# tle984x register map
Vendor: Infineon; File version: 1.9.5
CPU: CM0 r2p1, little endian, no MPU, no FPU, 2 interrupt priority bits
Registers are 32-bit, read-write, reset 0x0 unless marked. A register's access mark holds for its fields unless they carry their own. Offsets are from the block's base; [hi:lo] are bit positions; {n}, {i} and the like mark numbered series; 'fields as' and 'values as' point back to an identical list.

## SCUPM — System Control Unit - Power Modules (SCU-PM)
Base 0x50006000
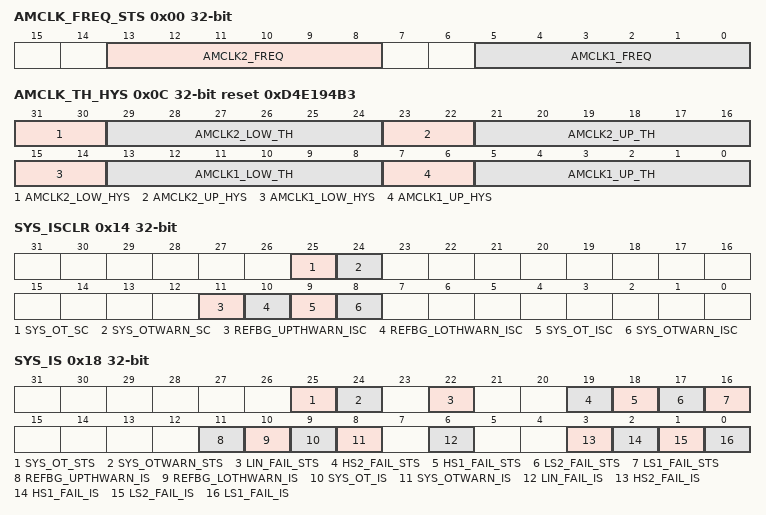
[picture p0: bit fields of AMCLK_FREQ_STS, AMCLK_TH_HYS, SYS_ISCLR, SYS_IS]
0x00 AMCLK_FREQ_STS ro — Analog module clock frequency status register
  [13:8] AMCLK2_FREQ — Current frequency of analog module clock 2 (TFILT_CLK)
  [5:0] AMCLK1_FREQ — Current frequency of analog module clock system clock (MI_CLK)
0x04 AMCLK_CTRL reset 0x1 — Analog module clock control register
  [0] CLKWDT_PD_N — Clock watchdog power down
    0=DISABLE (Clock watchdog disabled); 1=ENABLE (Clock watchdog enabled)
0x0C AMCLK_TH_HYS reset 0xD4E194B3 — Analog module clock limit register
  [31:30] AMCLK2_LOW_HYS — Analog module clock 2 (TFILT_CLK) lower hysteresis
  [29:24] AMCLK2_LOW_TH — Analog module clock 2 (TFILT_CLK) lower limit threshold
  [23:22] AMCLK2_UP_HYS — Analog module clock 2 (TFILT_CLK) upper hysteresis
  [21:16] AMCLK2_UP_TH — Analog module clock 2 (TFILT_CLK) upper limit threshold
  [15:14] AMCLK1_LOW_HYS — Analog module clock 1 (MI_CLK) lower hysteresis
  [13:8] AMCLK1_LOW_TH — Analog module clock 1 (MI_CLK) lower limit threshold
  [7:6] AMCLK1_UP_HYS — Analog module clock 1 (MI_CLK) upper hysteresis
  [5:0] AMCLK1_UP_TH — Analog module clock 1 (MI_CLK) upper limit threshold
0x14 SYS_ISCLR — System interrupt status clear register
  [all] fields
    0=NO_CLEAR (The interrupt status is not cleared); 1=CLEAR (The interrupt status is cleared)
  [25] SYS_OT_SC wo — System overtemperature shutdown status clear
  [24] SYS_OTWARN_SC wo — System overtemperature pre-warning status clear
  [11] REFBG_UPTHWARN_ISC wo — 8-bit ADC2 reference overvoltage interrupt status clear
  [10] REFBG_LOTHWARN_ISC wo — 8-bit ADC2 reference undervoltage interrupt status clear
  [9] SYS_OT_ISC wo — System overtemperature shutdown status clear
  [8] SYS_OTWARN_ISC wo — System overtemperature pre-warning status clear
0x18 SYS_IS — System interrupt status register
  [25] SYS_OT_STS — System overtemperature shutdown (ADC2, channel 6) status
    0=INACTIVE (No status set); 1=ACTIVE (At least one status set)
  [24] SYS_OTWARN_STS — System overtemperature pre-warning (ADC2, channel 6) status
    values as SYS_OT_STS
  [22] LIN_FAIL_STS ro — LIN fail status
    values as SYS_OT_STS
  [19] HS2_FAIL_STS ro — High-side driver 2 fail status
    values as SYS_OT_STS
  [18] HS1_FAIL_STS ro — High-side driver 1 fail status
    values as SYS_OT_STS
  [17] LS2_FAIL_STS ro — Low-side driver 2 fail status
    values as SYS_OT_STS
  [16] LS1_FAIL_STS ro — Low-side driver 1 fail status
    values as SYS_OT_STS
  [11] REFBG_UPTHWARN_IS — 8-bit ADC2 reference overvoltage (ADC2, channel 3) interrupt status
    0=INACTIVE (No interrupt status set); 1=ACTIVE (At least one interrupt status set)
  [10] REFBG_LOTHWARN_IS — 8-bit ADC2 reference undervoltage (ADC2, channel 3) interrupt status
    values as REFBG_UPTHWARN_IS
  [9] SYS_OT_IS — System overtemperature shutdown (ADC2, channel 6) interrupt status
    values as REFBG_UPTHWARN_IS
  [8] SYS_OTWARN_IS — System overtemperature prewarning (ADC2, channel 6) interrupt status
    values as REFBG_UPTHWARN_IS
  [6] LIN_FAIL_IS ro — LIN fail interrupt status
    values as SYS_OT_STS
  [3] HS2_FAIL_IS ro — High-side driver 2 fail interrupt status
    values as SYS_OT_STS
  [2] HS1_FAIL_IS ro — High-side driver 1 fail interrupt status
    values as SYS_OT_STS
  [1] LS2_FAIL_IS ro — Low-side driver 2 fail interrupt status
    values as SYS_OT_STS
  [0] LS1_FAIL_IS ro — Low-side driver 1 fail interrupt status
    values as SYS_OT_STS
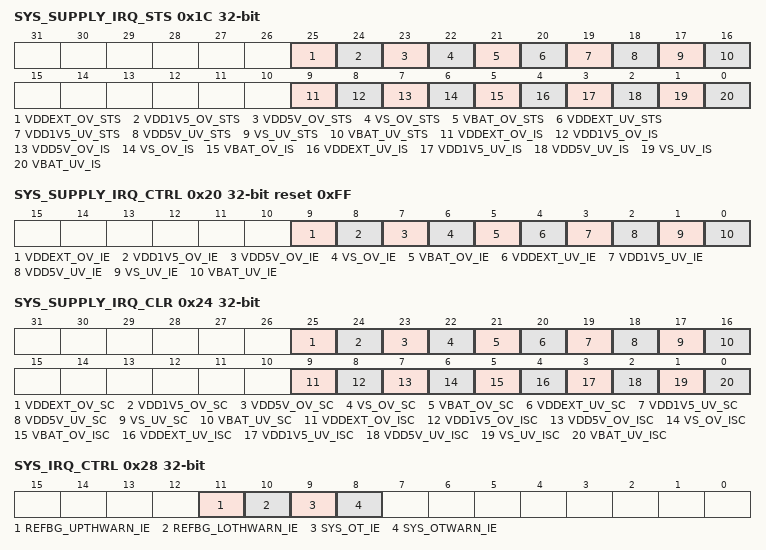
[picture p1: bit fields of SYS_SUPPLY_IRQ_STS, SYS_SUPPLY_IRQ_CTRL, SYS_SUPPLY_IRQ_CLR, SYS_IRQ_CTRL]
0x1C SYS_SUPPLY_IRQ_STS — System supply interrupt status register
  [25] VDDEXT_OV_STS — VDDEXT overvoltage status
    0=NO_OVERVOLTAGE (No overvoltage occurred); 1=OVERVOLTAGE (Overvoltage occurred)
  [24] VDD1V5_OV_STS — VDDC overvoltage status
    values as VDDEXT_OV_STS
  [23] VDD5V_OV_STS — VDDP overvoltage status
    values as VDDEXT_OV_STS
  [22] VS_OV_STS — VS overvoltage status
    values as VDDEXT_OV_STS
  [21] VBAT_OV_STS — VBAT overvoltage status
    values as VDDEXT_OV_STS
  [20] VDDEXT_UV_STS — VDDEXT undervoltage status
    0=NO_UNDERVOLTAGE (No undervoltage occurred); 1=UNDERVOLTAGE (Undervoltage occurred)
  [19] VDD1V5_UV_STS — VDDC undervoltage status
    values as VDDEXT_UV_STS
  [18] VDD5V_UV_STS — VDDP undervoltage status
    values as VDDEXT_UV_STS
  [17] VS_UV_STS — VS undervoltage status
    values as VDDEXT_UV_STS
  [16] VBAT_UV_STS — VBAT undervoltage status
    values as VDDEXT_UV_STS
  [9] VDDEXT_OV_IS — VDDEXT overvoltage interrupt status
    0=NO_INTERRUPT (No undervoltage interrupt occurred); 1=INTERRUPT (Undervoltage interrupt occurred)
  [8] VDD1V5_OV_IS — VDDC overvoltage interrupt status
    values as VDDEXT_OV_IS
  [7] VDD5V_OV_IS — VDDP overvoltage interrupt status
    values as VDDEXT_OV_IS
  [6] VS_OV_IS — VS overvoltage interrupt status
    values as VDDEXT_OV_IS
  [5] VBAT_OV_IS — VBAT overvoltage interrupt status
    values as VDDEXT_OV_IS
  [4] VDDEXT_UV_IS — VDDEXT undervoltage interrupt status
    values as VDDEXT_OV_IS
  [3] VDD1V5_UV_IS — VDDC undervoltage interrupt status
    values as VDDEXT_OV_IS
  [2] VDD5V_UV_IS — VDDP undervoltage interrupt status
    values as VDDEXT_OV_IS
  [1] VS_UV_IS — VS undervoltage interrupt status
    values as VDDEXT_OV_IS
  [0] VBAT_UV_IS — VBAT undervoltage interrupt status
    values as VDDEXT_OV_IS
0x20 SYS_SUPPLY_IRQ_CTRL reset 0xFF — System supply interrupt control register
  [all] fields
    0=DISABLED (Interrupt is disabled); 1=ENABLED (Interrupt is enabled)
  [9] VDDEXT_OV_IE — VDDEXT overvoltage interrupt enable
  [8] VDD1V5_OV_IE — VDDC overvoltage interrupt enable
  [7] VDD5V_OV_IE — VDDP overvoltage interrupt enable
  [6] VS_OV_IE — VS overvoltage interrupt enable
  [5] VBAT_OV_IE — VBAT overvoltage interrupt enable
  [4] VDDEXT_UV_IE — VDDEXT undervoltage interrupt enable
  [3] VDD1V5_UV_IE — VDDC undervoltage interrupt enable
  [2] VDD5V_UV_IE — VDDP undervoltage interrupt enable
  [1] VS_UV_IE — VS undervoltage interrupt enable
  [0] VBAT_UV_IE — VBAT undervoltage interrupt enable
0x24 SYS_SUPPLY_IRQ_CLR — System supply interrupt status clear register
  [all] fields
    values as the fields of SYS_ISCLR
  [25] VDDEXT_OV_SC wo — VDDEXT overvoltage status clear
  [24] VDD1V5_OV_SC wo — VDDC overvoltage status clear
  [23] VDD5V_OV_SC wo — VDDP overvoltage status clear
  [22] VS_OV_SC wo — VS overvoltage status clear
  [21] VBAT_OV_SC wo — VBAT overvoltage status clear
  [20] VDDEXT_UV_SC wo — VDDEXT undervoltage status clear
  [19] VDD1V5_UV_SC wo — VDDC undervoltage status clear
  [18] VDD5V_UV_SC wo — VDDP undervoltage status clear
  [17] VS_UV_SC wo — VS undervoltage status clear
  [16] VBAT_UV_SC wo — VBAT undervoltage status clear
  [9] VDDEXT_OV_ISC wo — VDDEXT overvoltage interrupt status clear
  [8] VDD1V5_OV_ISC wo — VDDC overvoltage interrupt status clear
  [7] VDD5V_OV_ISC wo — VDDP overvoltage interrupt status clear
  [6] VS_OV_ISC wo — VS overvoltage interrupt status clear
  [5] VBAT_OV_ISC wo — VBAT overvoltage interrupt status clear
  [4] VDDEXT_UV_ISC wo — VDDEXT undervoltage interrupt status clear
  [3] VDD1V5_UV_ISC wo — VDDC undervoltage interrupt status clear
  [2] VDD5V_UV_ISC wo — VDDP undervoltage interrupt status clear
  [1] VS_UV_ISC wo — VS undervoltage interrupt status clear
  [0] VBAT_UV_ISC wo — VBAT undervoltage interrupt status clear
0x28 SYS_IRQ_CTRL — System interrupt control register
  [all] fields
    values as the fields of SYS_SUPPLY_IRQ_CTRL
  [11] REFBG_UPTHWARN_IE — Reference voltage overvoltage interrupt enable
  [10] REFBG_LOTHWARN_IE — Reference voltage undervoltage interrupt enable
  [9] SYS_OT_IE — System overtemperature shutdown interrupt enable (leads to shutdown of system)
  [8] SYS_OTWARN_IE — System overtemperature warning interrupt enable
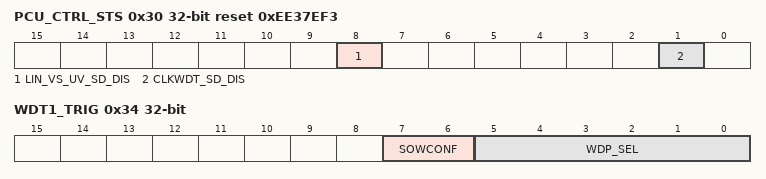
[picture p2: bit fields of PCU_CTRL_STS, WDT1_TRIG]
0x30 PCU_CTRL_STS reset 0xEE37EF3 — Power control unit control status register
  [8] LIN_VS_UV_SD_DIS — LIN module VS undervoltage transmitter shutdown
    0=ENABLE (Automatic shutdown for power modules in case of VS undervoltage enabled); 1=DISABLE (Automatic shutdown for power modules in case of VS undervoltage disabled)
  [1] CLKWDT_SD_DIS — Power modules clock watchdog shutdown disable
    0=ENABLE (Power devices will be switched off when clock watchdog occurs); 1=DISABLE (Power devices will not be shut down when clock watchdog occurs)
0x34 WDT1_TRIG — WDT1 watchdog control register
  [7:6] SOWCONF — Short open window configuration
    0=DIS (Short open windows disabled); 1=SOW1 (One successive short open window allowed); 2=SOW2 (Two successive short open windows allowed); 3=SOW3 (Three successive short open windows allowed)
  [5:0] WDP_SEL — Watchdog period selection and trigger
    0=SOW_TRIG (Trigger short open window); 1=WP1_1 (Watchdog period {$x*16} ms ({$x}*16)); 2=WP2_2 (Watchdog period {$x*16} ms ({$x}*16)); 3=WP3_3 (Watchdog period {$x*16} ms ({$x}*16)); 4=WP4_4 (Watchdog period {$x*16} ms ({$x}*16)); 5=WP5_5 (Watchdog period {$x*16} ms ({$x}*16)); 6=WP6_6 (Watchdog period {$x*16} ms ({$x}*16)); 7=WP7_7 (Watchdog period {$x*16} ms ({$x}*16)); 8=WP8_8 (Watchdog period {$x*16} ms ({$x}*16)); 9=WP9_9 (Watchdog period {$x*16} ms ({$x}*16)); 10=WP10_10 (Watchdog period {$x*16} ms ({$x}*16)); 11=WP11_11 (Watchdog period {$x*16} ms ({$x}*16)); 12=WP12_12 (Watchdog period {$x*16} ms ({$x}*16)); 13=WP13_13 (Watchdog period {$x*16} ms ({$x}*16)); 14=WP14_14 (Watchdog period {$x*16} ms ({$x}*16)); 15=WP15_15 (Watchdog period {$x*16} ms ({$x}*16)); 16=WP16_16 (Watchdog period {$x*16} ms ({$x}*16)); 17=WP17_17 (Watchdog period {$x*16} ms ({$x}*16)); 18=WP18_18 (Watchdog period {$x*16} ms ({$x}*16)); 19=WP19_19 (Watchdog period {$x*16} ms ({$x}*16)); 20=WP20_20 (Watchdog period {$x*16} ms ({$x}*16)); 21=WP21_21 (Watchdog period {$x*16} ms ({$x}*16)); 22=WP22_22 (Watchdog period {$x*16} ms ({$x}*16)); 23=WP23_23 (Watchdog period {$x*16} ms ({$x}*16)); 24=WP24_24 (Watchdog period {$x*16} ms ({$x}*16)); 25=WP25_25 (Watchdog period {$x*16} ms ({$x}*16)); 26=WP26_26 (Watchdog period {$x*16} ms ({$x}*16)); 27=WP27_27 (Watchdog period {$x*16} ms ({$x}*16)); 28=WP28_28 (Watchdog period {$x*16} ms ({$x}*16)); 29=WP29_29 (Watchdog period {$x*16} ms ({$x}*16)); 30=WP30_30 (Watchdog period {$x*16} ms ({$x}*16)); 31=WP31_31 (Watchdog period {$x*16} ms ({$x}*16)); 32=WP32_32 (Watchdog period {$x*16} ms ({$x}*16)); 33=WP33_33 (Watchdog period {$x*16} ms ({$x}*16)); 34=WP34_34 (Watchdog period {$x*16} ms ({$x}*16)); 35=WP35_35 (Watchdog period {$x*16} ms ({$x}*16)); 36=WP36_36 (Watchdog period {$x*16} ms ({$x}*16)); 37=WP37_37 (Watchdog period {$x*16} ms ({$x}*16)); 38=WP38_38 (Watchdog period {$x*16} ms ({$x}*16)); 39=WP39_39 (Watchdog period {$x*16} ms ({$x}*16)); 40=WP40_40 (Watchdog period {$x*16} ms ({$x}*16)); 41=WP41_41 (Watchdog period {$x*16} ms ({$x}*16)); 42=WP42_42 (Watchdog period {$x*16} ms ({$x}*16)); 43=WP43_43 (Watchdog period {$x*16} ms ({$x}*16)); 44=WP44_44 (Watchdog period {$x*16} ms ({$x}*16)); 45=WP45_45 (Watchdog period {$x*16} ms ({$x}*16)); 46=WP46_46 (Watchdog period {$x*16} ms ({$x}*16)); 47=WP47_47 (Watchdog period {$x*16} ms ({$x}*16)); 48=WP48_48 (Watchdog period {$x*16} ms ({$x}*16)); 49=WP49_49 (Watchdog period {$x*16} ms ({$x}*16)); 50=WP50_50 (Watchdog period {$x*16} ms ({$x}*16)); 51=WP51_51 (Watchdog period {$x*16} ms ({$x}*16)); 52=WP52_52 (Watchdog period {$x*16} ms ({$x}*16)); 53=WP53_53 (Watchdog period {$x*16} ms ({$x}*16)); 54=WP54_54 (Watchdog period {$x*16} ms ({$x}*16)); 55=WP55_55 (Watchdog period {$x*16} ms ({$x}*16)); 56=WP56_56 (Watchdog period {$x*16} ms ({$x}*16)); 57=WP57_57 (Watchdog period {$x*16} ms ({$x}*16)); 58=WP58_58 (Watchdog period {$x*16} ms ({$x}*16)); 59=WP59_59 (Watchdog period {$x*16} ms ({$x}*16)); 60=WP60_60 (Watchdog period {$x*16} ms ({$x}*16)); 61=WP61_61 (Watchdog period {$x*16} ms ({$x}*16)); 62=WP62_62 (Watchdog period {$x*16} ms ({$x}*16)); 63=WP63_63 (Watchdog period {$x*16} ms ({$x}*16))
0x6C STCALIB — System tick calibration register
  [25:0] STCALIB — System tick calibration
